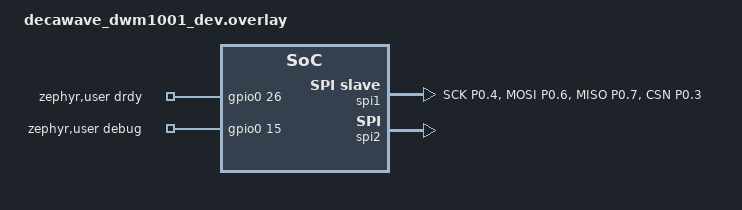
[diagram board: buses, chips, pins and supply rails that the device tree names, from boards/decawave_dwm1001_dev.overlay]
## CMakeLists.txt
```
cmake_minimum_required(VERSION 3.20.0)

find_package(Zephyr REQUIRED HINTS $ENV{ZEPHYR_BASE})
project(rtls_gateway)

target_sources(app PRIVATE
  src/main.c
  src/tag_table.c
)
```

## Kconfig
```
mainmenu "RTLS - Gateway"

menu "Gateway"

config RTLS_NODE_ID
	hex "Endereço curto do gateway"
	default 0x0001
	range 0x0001 0x0FFF
	help
	  As tags enviam POSITION para RTLS_ADDR_GATEWAY (0x0001); mude
	  apenas junto com rtls/frames.h.

config RTLS_GATEWAY_MAX_TAGS
	int "Capacidade da tabela de tags"
	default 16
	range 1 64

config RTLS_GATEWAY_TAG_TIMEOUT_MS
	int "Expiração de uma tag sem atualização (ms)"
	default 2000

config RTLS_GATEWAY_PUBLISH_MS
	int "Período de publicação do snapshot para o host (ms)"
	default 100

config RTLS_GATEWAY_CSV_OUTPUT
	bool "Imprime cada POSITION recebido em CSV na UART"
	default y
	help
	  Uma linha por POSITION: P,<tag>,<round>,<t_ms>,<x_mm>,<y_mm>,<z_mm>,
	  <sx_mm>,<sy_mm>,<sz_mm>,<n_ranges>,<flags>,<rx_cdbm>,<fp_cdbm>,<gw_ms>,
	  onde t_ms é o uptime da tag no POLL da rodada e gw_ms o uptime do
	  gateway na recepção. Lida por tools/rtls_log.py. O printk passa
	  pelo log diferido (CONFIG_LOG_PRINTK) e não bloqueia o rádio, mas
	  cada linha ocupa ~6 ms de UART a 115200 bps: com muitas tags,
	  desligue e use o SPI.

config RTLS_GATEWAY_STATS_PERIOD_S
	int "Período do resumo de recepção por tag (s; 0 desliga)"
	default 10

config RTLS_GATEWAY_BEACON
	bool "Transmite o BEACON do superquadro TDMA (M7)"
	help
	  Abre cada superquadro com um BEACON em broadcast (superquadro,
	  n_slots, slot_us). As tags com CONFIG_RTLS_TAG_TDMA=y só transmitem
	  no próprio slot depois de ouvi-lo (docs/03-protocolo-uwb.md, 5.2).
	  Desligado, as tags rodam em ciclo próprio (M3-M6).

config RTLS_GATEWAY_TDMA_SLOTS
	int "Slots de tag por superquadro"
	default 8
	range 1 32
	help
	  O superquadro dura 4 ms (BEACON) + slots x RTLS_GATEWAY_TDMA_SLOT_US.
	  8 x 12 ms = 100 ms: 8 tags a 10 Hz.

config RTLS_GATEWAY_TDMA_SLOT_US
	int "Duração do slot de cada tag (us)"
	default 12000
	range 2000 60000
	help
	  Precisa caber a rodada DS-TWR (~9,2 ms com 4 âncoras e 1 ms de
	  T_reply/T_slot), o EKF, o POSITION e uma guarda (docs/03, 5.3).

config RTLS_GATEWAY_SIM_TAGS
	int "Tags simuladas no snapshot para o host (teste do M6)"
	default 0
	range 0 32
	help
	  Acrescenta N registros sintéticos (IDs 0x1F00 + i, posição andando
	  em x e round avançando a cada snapshot) aos das tags reais. Serve
	  para testar a paginação e o CRC do SPI com mais de 9 tags (T6.3,
	  T6.4) sem montar a bancada. Deixe 0 em uso normal.

endmenu

source "Kconfig.zephyr"
```

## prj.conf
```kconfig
# Gateway: recebe POSITION das tags e entrega a tabela ao host via SPI escravo.

CONFIG_GPIO=y
CONFIG_SPI=y

CONFIG_LOG=y
CONFIG_LOG_MODE_DEFERRED=y
# O CSV (printk) passa pelo log diferido (CONFIG_LOG_PRINTK). Com o buffer
# padrão de 1 KB, um pico de linhas descarta as mais antigas; 4 KB dá folga.
CONFIG_LOG_BUFFER_SIZE=4096

CONFIG_RTLS_STATUS_LED=y
CONFIG_RTLS_PROTO=y
CONFIG_RTLS_HOST_IF=y

# M8: parâmetros na NVS (settings), shell na UART e watchdog.
CONFIG_FLASH=y
CONFIG_FLASH_MAP=y
CONFIG_NVS=y
CONFIG_SETTINGS=y
CONFIG_SHELL=y
CONFIG_REBOOT=y
CONFIG_WATCHDOG=y
# O CSV sai pelo backend de log do shell: filas maiores para não perder linhas.
CONFIG_SHELL_BACKEND_SERIAL_LOG_MESSAGE_QUEUE_SIZE=4096
CONFIG_SHELL_BACKEND_SERIAL_TX_RING_BUFFER_SIZE=64
CONFIG_RTLS_CONFIG=y
CONFIG_RTLS_WATCHDOG=y
```

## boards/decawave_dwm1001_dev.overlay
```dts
/*
 * Gateway: SPI1 do header RPi vira SPI escravo (SPIS) para o host, e P0.26
 * sinaliza dado pronto (DRDY). Mesmos pinos do SPI/IRQ do PANS.
 * Protocolo: docs/05-interface-spi-gateway.md.
 */

/ {
	chosen {
		rtls,host-spi = &spi1;
	};

	zephyr,user {
		drdy-gpios = <&gpio0 26 GPIO_ACTIVE_HIGH>;
		/* GPIO de debug (CONFIG_RTLS_DEBUG_GPIO): pulso a cada POSITION, pino 3 do RPi. */
		debug-gpios = <&gpio0 15 GPIO_ACTIVE_HIGH>;
	};
};

&pinctrl {
	spis1_default: spis1_default {
		group1 {
			psels = <NRF_PSEL(SPIS_SCK, 0, 4)>,
				<NRF_PSEL(SPIS_MOSI, 0, 6)>,
				<NRF_PSEL(SPIS_MISO, 0, 7)>,
				<NRF_PSEL(SPIS_CSN, 0, 3)>;
		};
	};

	spis1_sleep: spis1_sleep {
		group1 {
			psels = <NRF_PSEL(SPIS_SCK, 0, 4)>,
				<NRF_PSEL(SPIS_MOSI, 0, 6)>,
				<NRF_PSEL(SPIS_MISO, 0, 7)>,
				<NRF_PSEL(SPIS_CSN, 0, 3)>;
			low-power-enable;
		};
	};
};

&spi1 {
	compatible = "nordic,nrf-spis";
	status = "okay";
	/* 0x00 = "ainda não pronto" para o host enquanto os buffers não estão armados. */
	def-char = <0x00>;
	pinctrl-0 = <&spis1_default>;
	pinctrl-1 = <&spis1_sleep>;
	pinctrl-names = "default", "sleep";
	/delete-property/ cs-gpios;
};

/* Barramento do DW1000 (já habilitado na placa; explícito por segurança). */
&spi2 {
	status = "okay";
};
```

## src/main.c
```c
/*
 * Firmware do GATEWAY.
 *
 * Recebe os quadros POSITION das tags, mantém a tabela de tags e publica
 * snapshots periódicos para o host via SPI escravo.
 * Fluxo: docs/02-arquitetura.md, seção 4.3.
 */

#include <errno.h>
#include <string.h>

#include <zephyr/app_version.h>
#include <zephyr/kernel.h>
#include <zephyr/logging/log.h>
#include <zephyr/sys/printk.h>
#include <zephyr/sys/util.h>

#include <rtls/config.h>
#include <rtls/debug_gpio.h>
#include <rtls/dw1000.h>
#include <rtls/frames.h>
#include <rtls/host_if.h>
#include <rtls/status_led.h>
#include <rtls/tdma.h>
#include <rtls/watchdog.h>

#include "tag_table.h"

LOG_MODULE_REGISTER(gateway, LOG_LEVEL_INF);

#define SNAPSHOT_RECORDS (CONFIG_RTLS_GATEWAY_MAX_TAGS + CONFIG_RTLS_GATEWAY_SIM_TAGS)

BUILD_ASSERT(SNAPSHOT_RECORDS <= CONFIG_RTLS_HOST_IF_MAX_RECORDS,
	     "aumente CONFIG_RTLS_HOST_IF_MAX_RECORDS");

/* Primeiro ID das tags simuladas (CONFIG_RTLS_GATEWAY_SIM_TAGS). */
#define SIM_TAG_BASE 0x1F00

/* Superquadro TDMA: 4 ms de BEACON + slots de tag (docs/03, seção 5.2). */
#define SUPERFRAME_US                                                                              \
	(RTLS_TDMA_BEACON_SEG_US + CONFIG_RTLS_GATEWAY_TDMA_SLOTS * CONFIG_RTLS_GATEWAY_TDMA_SLOT_US)

static uint8_t mac_seq;

/* PAN do registro de parâmetros (M8); o ID do gateway é fixo (RTLS_ADDR_GATEWAY). */
static uint16_t pan_id;

/* BEACONs desde o último resumo (T7.1: período estável). */
static struct {
	uint32_t sent;
	uint32_t errors;
	int64_t max_late_us; /**< maior atraso em relação à grade de 100 ms */
} beacon_stats;

static int64_t now_us(void)
{
	return (int64_t)k_ticks_to_us_floor64(k_uptime_ticks());
}

/* BEACON em broadcast: abre o superquadro @p superframe. */
static int send_beacon(uint16_t superframe)
{
	const struct rtls_msg_beacon msg = {
		.type = RTLS_MSG_BEACON,
		.superframe = superframe,
		.n_slots = CONFIG_RTLS_GATEWAY_TDMA_SLOTS,
		.slot_us = CONFIG_RTLS_GATEWAY_TDMA_SLOT_US,
	};
	struct rtls_mac_hdr hdr;
	uint8_t frame[RTLS_FRAME_MAX_LEN];
	int len;

	rtls_mac_hdr_init(&hdr, mac_seq++, pan_id, RTLS_ADDR_BROADCAST, CONFIG_RTLS_NODE_ID);
	len = rtls_frame_build(frame, sizeof(frame), &hdr, &msg, sizeof(msg));
	if (len < 0) {
		return len;
	}

	/* O RX já está desligado: dw1000_receive() o desliga no timeout. */
	return dw1000_transmit(frame, len, NULL, NULL);
}

/* Uma linha CSV por POSITION recebido (lida por tools/rtls_log.py). */
static void print_position(uint16_t tag_id, const struct rtls_msg_position *msg,
			   const struct dw1000_rx_info *info, int64_t now_ms)
{
	if (!IS_ENABLED(CONFIG_RTLS_GATEWAY_CSV_OUTPUT)) {
		return;
	}

	printk("P,%04x,%u,%u,%d,%d,%d,%u,%u,%u,%u,%u,%d,%d,%u\n", tag_id, msg->round, msg->t_ms,
	       msg->pos_mm[0], msg->pos_mm[1], msg->pos_mm[2], msg->std_mm[0], msg->std_mm[1],
	       msg->std_mm[2], msg->n_ranges, msg->flags, info->rx_power_cdbm,
	       info->fp_power_cdbm, (uint32_t)now_ms);
}

static void handle_frame(const uint8_t *frame, size_t len, const struct dw1000_rx_info *info)
{
	const int64_t now_ms = k_uptime_get();
	struct rtls_msg_position msg;
	struct rtls_mac_hdr hdr;
	const uint8_t *payload;
	size_t payload_len;
	int err;

	if (rtls_frame_parse(frame, len, pan_id, &hdr, &payload, &payload_len) !=
	    RTLS_MSG_POSITION) {
		return;
	}
	/* Instante da recepção para o analisador lógico (T5.2). */
	rtls_debug_gpio_pulse();

	memcpy(&msg, payload, sizeof(msg));
	err = tag_table_update(hdr.src, &msg, info->rx_power_cdbm, now_ms);
	if (err == -ENOMEM) {
		LOG_WRN("tabela cheia; tag 0x%04x ignorada", hdr.src);
		return;
	}
	if (err) {
		return;
	}

	print_position(hdr.src, &msg, info, now_ms);
	rtls_status_led_activity();
}

/* Resumo por tag: POSITION recebidos e rodadas sem POSITION (lacunas de round). */
static void log_stats(void)
{
	static struct tag_stats stats[CONFIG_RTLS_GATEWAY_MAX_TAGS];
	const size_t n = tag_table_get_stats(stats, ARRAY_SIZE(stats), true);

	if (IS_ENABLED(CONFIG_RTLS_GATEWAY_BEACON)) {
		LOG_INF("GW: %u BEACONs, %u erros de TX, atraso max %d us", beacon_stats.sent,
			beacon_stats.errors, (int)beacon_stats.max_late_us);
		memset(&beacon_stats, 0, sizeof(beacon_stats));
	}

	if (n == 0) {
		LOG_INF("GW: nenhuma tag ativa");
		return;
	}

	for (size_t i = 0; i < n; i++) {
		const struct tag_stats *st = &stats[i];
		const uint32_t rounds = st->received + st->lost;

		if (st->received == 0) {
			continue;
		}
		LOG_INF("GW: tag 0x%04x: %u posicoes, %u lacunas (%u%% recebidas), RX %d dBm",
			st->tag_id, st->received, st->lost, 100U * st->received / rounds,
			st->rx_power_sum_cdbm / (int32_t)st->received / 100);
	}
}

/*
 * Registros sintéticos para testar a paginação do SPI (T6.3/T6.4): cada tag
 * anda 10 mm em x por snapshot, numa faixa de 6 m, e o round avança.
 */
static size_t add_sim_tags(struct rtls_tag_record *out)
{
	static uint8_t sim_round;

	sim_round++;
	for (int i = 0; i < CONFIG_RTLS_GATEWAY_SIM_TAGS; i++) {
		out[i] = (struct rtls_tag_record){
			.tag_id = SIM_TAG_BASE + i,
			.round = sim_round,
			.n_ranges = 4,
			.flags = RTLS_POS_FLAG_VALID,
			.rssi_dbm = -80,
			.pos_mm = {1000 + (sim_round * 10 + i * 500) % 6000, 500 * i, 1000},
			.std_mm = {50, 50, 0},
		};
	}

	return CONFIG_RTLS_GATEWAY_SIM_TAGS;
}

static void publish_snapshot(void)
{
	static struct rtls_tag_record records[SNAPSHOT_RECORDS];
	size_t n = tag_table_snapshot(records, CONFIG_RTLS_GATEWAY_MAX_TAGS, k_uptime_get());

	if (CONFIG_RTLS_GATEWAY_SIM_TAGS > 0) {
		n += add_sim_tags(&records[n]);
	}
	(void)rtls_host_if_publish(records, n);
}

static void apply_antenna_delay(void)
{
	const uint16_t tx = (uint16_t)rtls_config_get(RTLS_CFG_TX_ANT_DLY);
	const uint16_t rx = (uint16_t)rtls_config_get(RTLS_CFG_RX_ANT_DLY);

	if (dw1000_set_antenna_delay(tx, rx) == 0) {
		LOG_INF("atrasos de antena: TX %u, RX %u", tx, rx);
	}
}

/* Parâmetros de classe imediata alterados pelo shell; o PAN vale no próximo boot. */
static void apply_config_changes(void)
{
	uint16_t key;

	while ((key = rtls_config_next_change()) != 0) {
		if (key == RTLS_CFG_TX_ANT_DLY || key == RTLS_CFG_RX_ANT_DLY) {
			apply_antenna_delay();
		}
	}
}

static int radio_init(void)
{
	const struct dw1000_phy_config phy = DW1000_PHY_CONFIG_DEFAULT(pan_id, CONFIG_RTLS_NODE_ID);
	int err;

	err = dw1000_init();
	if (err == 0) {
		err = dw1000_configure(&phy);
	}
	if (err == 0) {
		apply_antenna_delay();
	}
	return err;
}

int main(void)
{
	/* Anunciado ao host em RTLS_INFO_GET; versão do arquivo VERSION do app. */
	const struct rtls_host_if_info host_info = {
		.fw_version = {APP_VERSION_MAJOR, APP_VERSION_MINOR, APP_PATCHLEVEL},
		.gateway_id = CONFIG_RTLS_NODE_ID,
		.capacity = CONFIG_RTLS_GATEWAY_MAX_TAGS,
		.superframe_ms = IS_ENABLED(CONFIG_RTLS_GATEWAY_BEACON) ? SUPERFRAME_US / 1000
									: CONFIG_RTLS_GATEWAY_PUBLISH_MS,
	};
	uint8_t frame[RTLS_FRAME_MAX_LEN];
	struct dw1000_rx_info info;
	int64_t next_publish_us, next_stats_us, next_beacon_us;
	uint16_t superframe = 0;
	int err;

	/* Falha da NVS: segue com os padrões do Kconfig (já registrado no log). */
	(void)rtls_config_init();
	pan_id = (uint16_t)rtls_config_get(RTLS_CFG_PAN_ID);

	LOG_INF("RTLS gateway 0x%04x v%s: ate %d tags, PAN 0x%04x", CONFIG_RTLS_NODE_ID,
		APP_VERSION_STRING, CONFIG_RTLS_GATEWAY_MAX_TAGS, pan_id);
	if (CONFIG_RTLS_GATEWAY_SIM_TAGS > 0) {
		LOG_WRN("modo de teste: %d tags simuladas no snapshot (0x%04x...)",
			CONFIG_RTLS_GATEWAY_SIM_TAGS, SIM_TAG_BASE);
	}
	if (IS_ENABLED(CONFIG_RTLS_GATEWAY_BEACON)) {
		LOG_INF("TDMA: BEACON a cada %d us, %d slots de %d us", SUPERFRAME_US,
			CONFIG_RTLS_GATEWAY_TDMA_SLOTS, CONFIG_RTLS_GATEWAY_TDMA_SLOT_US);
	}

	err = rtls_status_led_init();
	if (err) {
		LOG_WRN("LEDs indisponiveis (%d)", err);
	}
	err = rtls_debug_gpio_init();
	if (err) {
		LOG_WRN("GPIO de debug indisponivel (%d)", err);
	}

	tag_table_init();

	err = rtls_host_if_init(&host_info);
	if (err) {
		/* Segue sem host: as posições continuam no log. */
		LOG_ERR("interface com o host indisponivel (%d)", err);
	}

	err = radio_init();
	if (err) {
		LOG_ERR("DW1000 indisponivel (%d)", err);
		rtls_status_led_error(true);
		return 0;
	}

	err = rtls_watchdog_init();
	if (err) {
		LOG_WRN("sem watchdog (%d)", err);
	}

	/* Agenda em µs: o BEACON precisa de uma grade estável de 100 ms. */
	next_beacon_us = now_us();
	next_publish_us = now_us() + CONFIG_RTLS_GATEWAY_PUBLISH_MS * 1000LL;
	next_stats_us = now_us() + CONFIG_RTLS_GATEWAY_STATS_PERIOD_S * 1000000LL;
	while (true) {
		int64_t wake_us = next_publish_us;
		int len;

		/* O laço volta pelo menos a cada snapshot (100 ms). */
		rtls_watchdog_feed();
		apply_config_changes();

		if (IS_ENABLED(CONFIG_RTLS_GATEWAY_BEACON)) {
			wake_us = MIN(wake_us, next_beacon_us);
		}
		len = dw1000_receive(frame, sizeof(frame), &info,
				     K_TIMEOUT_ABS_TICKS(k_us_to_ticks_ceil64(MAX(wake_us, 0))));
		if (len > 0) {
			handle_frame(frame, (size_t)len, &info);
		}

		if (IS_ENABLED(CONFIG_RTLS_GATEWAY_BEACON) && now_us() >= next_beacon_us) {
			const int64_t late_us = now_us() - next_beacon_us;

			if (send_beacon(superframe++) == 0) {
				beacon_stats.sent++;
				beacon_stats.max_late_us = MAX(beacon_stats.max_late_us, late_us);
			} else {
				beacon_stats.errors++;
			}
			next_beacon_us += SUPERFRAME_US;
			/* Atrasou mais de um superquadro: recomeça a grade a partir de agora. */
			if (now_us() >= next_beacon_us) {
				next_beacon_us = now_us() + SUPERFRAME_US;
			}
		}

		if (now_us() >= next_publish_us) {
			publish_snapshot();
			next_publish_us += CONFIG_RTLS_GATEWAY_PUBLISH_MS * 1000LL;
		}

		if (CONFIG_RTLS_GATEWAY_STATS_PERIOD_S > 0 && now_us() >= next_stats_us) {
			log_stats();
			next_stats_us += CONFIG_RTLS_GATEWAY_STATS_PERIOD_S * 1000000LL;
		}
	}

	return 0;
}
```

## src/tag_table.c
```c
#include <errno.h>
#include <string.h>

#include <zephyr/kernel.h>
#include <zephyr/sys/util.h>

#include "tag_table.h"

struct tag_entry {
	bool used;
	int64_t last_ms;
	struct rtls_tag_record rec;
	struct rtls_round_tracker trk;
	struct tag_stats stats;
};

static struct tag_entry table[CONFIG_RTLS_GATEWAY_MAX_TAGS];

void tag_table_init(void)
{
	memset(table, 0, sizeof(table));
}

int tag_table_update(uint16_t tag_id, const struct rtls_msg_position *msg,
		     int16_t rx_power_cdbm, int64_t now_ms)
{
	struct tag_entry *entry = NULL;
	struct tag_entry *free_entry = NULL;
	int lost;

	for (size_t i = 0; i < ARRAY_SIZE(table); i++) {
		if (table[i].used && table[i].rec.tag_id == tag_id) {
			entry = &table[i];
			break;
		}
		if (!table[i].used && free_entry == NULL) {
			free_entry = &table[i];
		}
	}

	if (entry == NULL) {
		if (free_entry == NULL) {
			return -ENOMEM;
		}
		/* entrada nova (ou que expirou): a sequência de round recomeça */
		entry = free_entry;
		memset(entry, 0, sizeof(*entry));
		entry->used = true;
		entry->stats.tag_id = tag_id;
	}

	lost = rtls_round_tracker_update(&entry->trk, msg->round, msg->t_ms);
	if (lost < 0) {
		return lost;
	}
	entry->stats.received++;
	entry->stats.lost += (uint32_t)lost;
	entry->stats.rx_power_sum_cdbm += rx_power_cdbm;

	entry->last_ms = now_ms;
	entry->rec.tag_id = tag_id;
	entry->rec.round = msg->round;
	entry->rec.n_ranges = msg->n_ranges;
	entry->rec.flags = msg->flags;
	entry->rec.rssi_dbm = (int8_t)(rx_power_cdbm / 100);
	entry->rec.age_ms = 0;
	for (int k = 0; k < 3; k++) {
		entry->rec.pos_mm[k] = msg->pos_mm[k];
		entry->rec.std_mm[k] = msg->std_mm[k];
	}

	return 0;
}

size_t tag_table_snapshot(struct rtls_tag_record *out, size_t max, int64_t now_ms)
{
	size_t n = 0;

	for (size_t i = 0; i < ARRAY_SIZE(table); i++) {
		const int64_t age = now_ms - table[i].last_ms;

		if (!table[i].used) {
			continue;
		}
		if (age > CONFIG_RTLS_GATEWAY_TAG_TIMEOUT_MS) {
			table[i].used = false;
			continue;
		}
		if (n < max) {
			out[n] = table[i].rec;
			out[n].age_ms = (uint16_t)MIN(age, (int64_t)UINT16_MAX);
			n++;
		}
	}

	return n;
}

size_t tag_table_get_stats(struct tag_stats *out, size_t max, bool reset)
{
	size_t n = 0;

	for (size_t i = 0; i < ARRAY_SIZE(table) && n < max; i++) {
		if (!table[i].used) {
			continue;
		}
		out[n++] = table[i].stats;
		if (reset) {
			table[i].stats.received = 0;
			table[i].stats.lost = 0;
			table[i].stats.rx_power_sum_cdbm = 0;
		}
	}

	return n;
}
```

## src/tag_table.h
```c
/*
 * Tabela das tags vistas pelo gateway. Acessada só pela thread main.
 */

#ifndef TAG_TABLE_H_
#define TAG_TABLE_H_

#include <stdbool.h>
#include <stddef.h>
#include <stdint.h>

#include <rtls/frames.h>
#include <rtls/host_if.h>

/** Contadores de uma tag desde o último tag_table_get_stats(..., true). */
struct tag_stats {
	uint16_t tag_id;
	uint32_t received; /**< POSITION recebidos */
	uint32_t lost;     /**< rodadas sem POSITION, pelas lacunas de `round` */
	int32_t rx_power_sum_cdbm;
};

void tag_table_init(void);

/**
 * Insere ou atualiza a entrada da tag @p tag_id com um POSITION recebido e
 * conta as lacunas de `round` (rtls_round_tracker_update()).
 *
 * @retval 0 entrada atualizada
 * @retval -ENOMEM tabela cheia
 * @retval -EALREADY POSITION repetido (ignorado)
 */
int tag_table_update(uint16_t tag_id, const struct rtls_msg_position *msg,
		     int16_t rx_power_cdbm, int64_t now_ms);

/**
 * Remove as entradas expiradas e copia as ativas para @p out, com age_ms
 * calculado em @p now_ms.
 *
 * @return quantidade de registros copiados
 */
size_t tag_table_snapshot(struct rtls_tag_record *out, size_t max, int64_t now_ms);

/**
 * Copia os contadores das tags ativas e, se @p reset, zera-os.
 *
 * @return quantidade de tags copiadas
 */
size_t tag_table_get_stats(struct tag_stats *out, size_t max, bool reset);

#endif /* TAG_TABLE_H_ */
```
